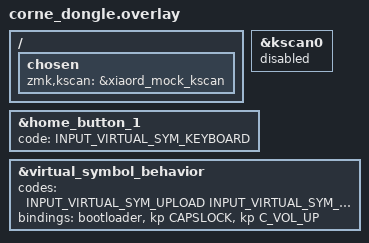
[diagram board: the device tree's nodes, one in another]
#include <dt-bindings/zmk/corne.dtsi>
#include <dt-bindings/xiaord/input_codes.h>
#include <dt-bindings/zmk/keys.h>
#include <dt-bindings/zmk/outputs.h>

&kscan0 { status = "disabled"; };
/ { chosen { zmk,kscan = &xiaord_mock_kscan; }; };

// Change the icon at position 1 to show a keyboard symbol.
&home_button_1 { code = <INPUT_VIRTUAL_SYM_KEYBOARD>; };

// Update virtual_symbol_behavior to map the new icon to a behavior.
// You must rewrite the entire codes/bindings table — DTS does not support
// partial array overrides, so all entries must be listed.
&virtual_symbol_behavior {
    codes = <
        INPUT_VIRTUAL_SYM_UPLOAD
        INPUT_VIRTUAL_SYM_KEYBOARD      /* replaces IMAGE at position 1 */
        INPUT_VIRTUAL_SYM_VOLUME_MAX
        /* ... all other codes you want to handle ... */
    >;
    bindings = <
        &bootloader
        &kp CAPSLOCK                    /* new binding for KEYBOARD icon */
        &kp C_VOL_UP
        /* ... matching bindings for each code above ... */
    >;
};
